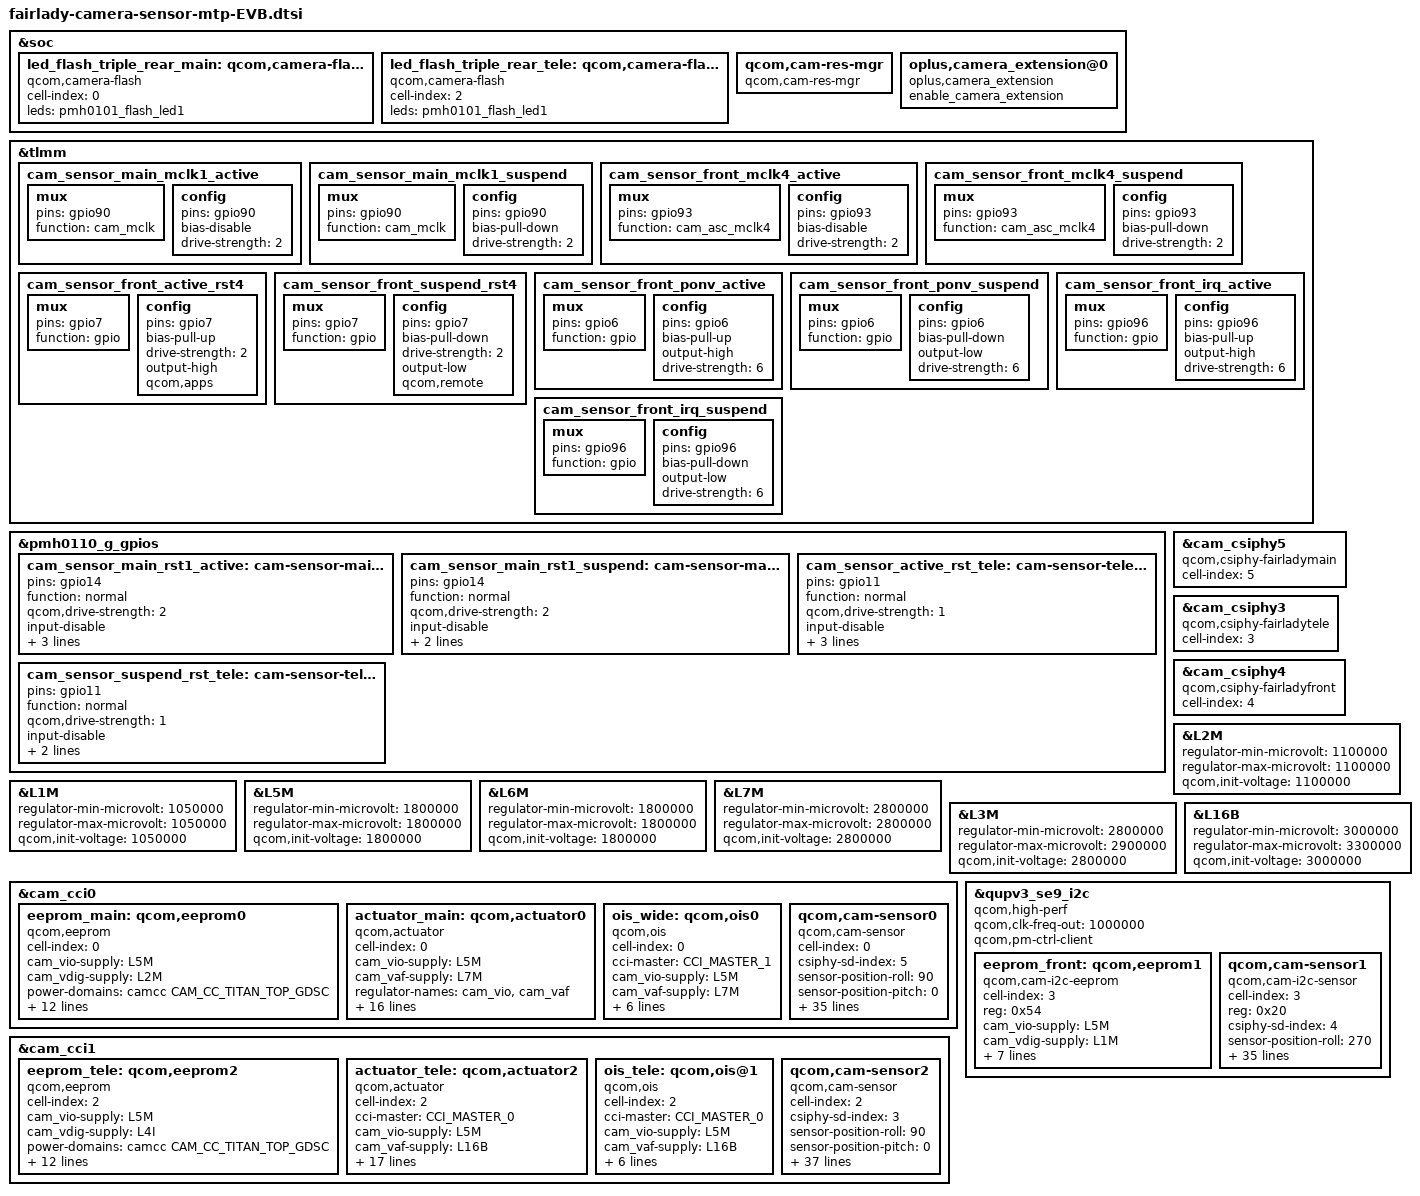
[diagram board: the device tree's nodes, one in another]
// SPDX-License-Identifier: BSD-3-Clause
/*
 * Copyright (c) 2024 Qualcomm Innovation Center, Inc. All rights reserved.
 */

#include <dt-bindings/msm-camera.h>
#include "ftm_camera_settings.dtsi"

&soc {

	led_flash_triple_rear_main: qcom,camera-flash0 {
		cell-index = <0>;
		compatible = "qcom,camera-flash";
		leds = <&pmh0101_flash_led1>;
		status = "ok";
	};

	led_flash_triple_rear_tele: qcom,camera-flash2 {
		cell-index = <2>;
		compatible = "qcom,camera-flash";
		leds = <&pmh0101_flash_led1>;
		status = "ok";
	};

	qcom,cam-res-mgr {
		compatible = "qcom,cam-res-mgr";
		status = "ok";
	};

	oplus,camera_extension@0 {
		compatible = "oplus,camera_extension";
		enable_camera_extension;
		status = "ok";
	};
};


&tlmm {
	cam_sensor_main_mclk1_active: cam_sensor_main_mclk1_active {
		/* MCLK1 */
		mux {
			pins = "gpio90";
			function = "cam_mclk";
		};

		config {
			pins = "gpio90";
			bias-disable; /* No PULL */
			drive-strength = <2>; /* 2 MA */
		};
	};

	cam_sensor_main_mclk1_suspend: cam_sensor_main_mclk1_suspend {
		/* MCLK1 */
		mux {
			pins = "gpio90";
			function = "cam_mclk";
		};

		config {
			pins = "gpio90";
			bias-pull-down; /* PULL DOWN */
			drive-strength = <2>; /* 2 MA */
		};
	};

	cam_sensor_front_mclk4_active: cam_sensor_front_mclk4_active {
		/* MCLK4 */
		mux {
			pins = "gpio93";
			function = "cam_asc_mclk4";
		};

		config {
			pins = "gpio93";
			bias-disable; /* No PULL */
			drive-strength = <2>; /* 2 MA */
		};
	};

	cam_sensor_front_mclk4_suspend: cam_sensor_front_mclk4_suspend {
		/* MCLK4 */
		mux {
			pins = "gpio93";
			function = "cam_asc_mclk4";
		};

		config {
			pins = "gpio93";
			bias-pull-down; /* PULL DOWN */
			drive-strength = <2>; /* 2 MA */
		};
	};

	cam_sensor_front_active_rst4: cam_sensor_front_active_rst4 {
		mux {
			pins = "gpio7";
			function = "gpio";
		};

		config {
			pins = "gpio7";
			bias-pull-up; /* PULL UP*/
			drive-strength = <2>; /* 2 MA */
			output-high;
			qcom,apps;
		};
	};

	cam_sensor_front_suspend_rst4: cam_sensor_front_suspend_rst4 {
		mux {
			pins = "gpio7";
			function = "gpio";
		};

		config {
			pins = "gpio7";
			bias-pull-down; /* PULL DOWN */
			drive-strength = <2>; /* 2 MA */
			output-low;
			qcom,remote;
		};
	};

	cam_sensor_front_ponv_active: cam_sensor_front_ponv_active {
		/* PONV */
		mux {
			pins = "gpio6";
			function = "gpio";
		};

		config {
			pins = "gpio6";
			bias-pull-up; /* PULL UP*/
			output-high;
			drive-strength = <6>; /* 2 MA */
		};
	};

	cam_sensor_front_ponv_suspend: cam_sensor_front_ponv_suspend {
		/* PONV */
		mux {
			pins = "gpio6";
			function = "gpio";
		};

		config {
			pins = "gpio6";


			bias-pull-down; /* PULL DOWN */
			output-low;
			drive-strength = <6>; /* 2 MA */
		};
	};

	cam_sensor_front_irq_active: cam_sensor_front_irq_active {
		/* TRQ */
		mux {
			pins = "gpio96";
			function = "gpio";
		};

		config {
			pins = "gpio96";
			bias-pull-up; /* PULL UP*/
			output-high;
			drive-strength = <6>; /* 2 MA */
		};
	};

	cam_sensor_front_irq_suspend: cam_sensor_front_irq_suspend {
		/* IRQ */
		mux {
			pins = "gpio96";
			function = "gpio";
		};

		config {
			pins = "gpio96";


			bias-pull-down; /* PULL DOWN */
			output-low;
			drive-strength = <6>; /* 2 MA */
		};
	};
};


&pmh0110_g_gpios {
    cam_sensor_main_rst1_active: cam-sensor-main-rst1-active-state {
		pins = "gpio14";
		function = "normal";
		qcom,drive-strength = <2>;
		input-disable;
		output-enable;
		output-high;
		power-source = <1>; /* 1.2 V */
	};

	cam_sensor_main_rst1_suspend: cam-sensor-main-rst1-suspend-state {
		pins = "gpio14";
		function = "normal";
		qcom,drive-strength = <2>;
		input-disable;
		output-enable;
		output-low;
	};

	cam_sensor_active_rst_tele: cam-sensor-tele-active-state {
		pins = "gpio11";
		function = "normal";
		qcom,drive-strength = <1>;
		input-disable;
		output-enable;
		output-high;
		power-source = <1>; /* 1.2 V */
	};
	
	cam_sensor_suspend_rst_tele: cam-sensor-tele-suspend-state {
		pins = "gpio11";
		function = "normal";
		qcom,drive-strength = <1>;
		input-disable;
		output-enable;
		output-low;
	};
};

&cam_csiphy5{
	cell-index = <5>;
	compatible = "qcom,csiphy-fairladymain", "qcom,csiphy";
};

&cam_csiphy3{
	cell-index = <3>;
	compatible = "qcom,csiphy-fairladytele", "qcom,csiphy";
};

&cam_csiphy4{
	cell-index = <4>;
	compatible = "qcom,csiphy-fairladyfront", "qcom,csiphy";
};

&L2M {
  regulator-min-microvolt = <1100000>;
  regulator-max-microvolt = <1100000>;
  qcom,init-voltage = <1100000>;
};

&L1M {
  regulator-min-microvolt = <1050000>;
  regulator-max-microvolt = <1050000>;
  qcom,init-voltage = <1050000>;
};

&L5M {
  regulator-min-microvolt = <1800000>;
  regulator-max-microvolt = <1800000>;
  qcom,init-voltage = <1800000>;
};

&L6M {
  regulator-min-microvolt = <1800000>;
  regulator-max-microvolt = <1800000>;
  qcom,init-voltage = <1800000>;
};

&L7M {
  regulator-min-microvolt = <2800000>;
  regulator-max-microvolt = <2800000>;
  qcom,init-voltage = <2800000>;
};

&L3M {
  regulator-min-microvolt = <2800000>;
  regulator-max-microvolt = <2900000>;
  qcom,init-voltage = <2800000>;
};

&L16B {
	regulator-min-microvolt = <3000000>;
	regulator-max-microvolt = <3300000>;
	qcom,init-voltage = <3000000>;
};

&cam_cci0 {
	eeprom_main: qcom,eeprom0 {
		cell-index = <0>;
		compatible = "qcom,eeprom";
		cam_vio-supply = <&L5M>;
		cam_vdig-supply = <&L2M>;
		power-domains = <&camcc CAM_CC_TITAN_TOP_GDSC>;
		cam_vana-supply = <&L3M>;
		cam_vaf-supply = <&L7M>;
		cam_v_custom1-supply = <&L6M>;
		regulator-names = "cam_vio", "cam_vdig", "cam_vana",
			"cam_vaf", "cam_v_custom1";
		rgltr-cntrl-support;
		rgltr-min-voltage = <1800000 1100000 2800000 2800000 1800000>;
		rgltr-max-voltage = <1800000 1100000 2800000 2800000 1800000>;
		rgltr-load-current = <3000 15000 3000 6000 3000>;
		cci-master = <CCI_MASTER_1>;
		status = "ok";
	};

	actuator_main: qcom,actuator0 {
		cell-index = <0>;
		compatible = "qcom,actuator";
		cam_vio-supply = <&L5M>;
		cam_vaf-supply = <&L7M>;
		regulator-names = "cam_vio", "cam_vaf";
		rgltr-cntrl-support;
		rgltr-min-voltage = <1800000 2800000>;
		rgltr-max-voltage = <1800000 2800000>;
		rgltr-load-current = <3000 6000>;
		cci-master = <CCI_MASTER_1>;
		actuator,name = "dw9827c_main";
		cci_client_sid = <0x18>;
		sds-lock-support;
		//                       reg_addr   addr_type   reg_data    data_type   delay       data_mask
		sds-lock-reg-setting = < 0x02           1         0x40        1          10            0x00 >,
		                       < 0x02           1         0x40        1          10            0x00 >,
		                       < 0x00           1         0x80        1          5             0x00 >,
		                       < 0x02           1         0x00        1          5             0x00 >;
		disable-auto-standby;
		//                                   reg_addr   addr_type   reg_data    data_type   delay       data_mask
		disable-auto-standby-reg-setting = < 0x02           1         0x40        1          5            0x00 >,
		                                   < 0x34           1         0x85        1          1            0x00 >,
		                                   < 0x7D           1         0x00        1          1            0x00 >,
		                                   < 0x03           1         0x01        1          10           0x00 >,
		                                   < 0x34           1         0x52        1          1            0x00 >,
		                                   < 0x04           1         0x01        1          20           0x00 >;
		status = "ok";
	};

	ois_wide: qcom,ois0 {
		cell-index = <0>;
		compatible = "qcom,ois";
		cci-master = <CCI_MASTER_1>;
		cam_vio-supply = <&L5M>;
		cam_vaf-supply = <&L7M>;
		power-domains = <&camcc CAM_CC_TITAN_TOP_GDSC>;
		regulator-names = "cam_vio","cam_vaf";
		rgltr-cntrl-support;
		rgltr-min-voltage = <1800000 2800000>;
		rgltr-max-voltage = <1800000 2800000>;
		rgltr-load-current = <3000 6000>;
		// ois_gyro,position=<3>;
		// ois_gyro,type=<3>;
		// ois,type=<0>;
		// //ois,name="bu63169";//??
		// ois_module,vendor=<1>;
		// ois_actuator,vednor=<2>;
		// ois,fw=<1>;
		status = "ok";
	};

	//main sensor
	qcom,cam-sensor0 {
		cell-index = <0>;
		compatible = "qcom,cam-sensor";
		csiphy-sd-index = <5>;
		sensor-position-roll = <90>;
		sensor-position-pitch = <0>;
		sensor-position-yaw = <180>;
		eeprom-src = <&eeprom_main>;
		actuator-src = <&actuator_main>;
		ois-src = <&ois_wide>;
		led-flash-src = <&led_flash_triple_rear_main>;
		cam_vio-supply = <&L5M>;
		cam_vdig-supply = <&L2M>;
		power-domains = <&camcc CAM_CC_TITAN_TOP_GDSC>;
		cam_vana-supply = <&L3M>;
		cam_vaf-supply = <&L7M>;
		cam_v_custom1-supply = <&L6M>;
		regulator-names = "cam_vio", "cam_vdig", "cam_vana",
			"cam_vaf", "cam_v_custom1";
		rgltr-cntrl-support;
		rgltr-min-voltage = <1800000 1100000 2800000 2800000 1800000>;
		rgltr-max-voltage = <1800000 1100000 2800000 2800000 1800000>;
		rgltr-load-current = <3000 15000 3000 6000 3000>;
		gpio-no-mux = <0>;
		pinctrl-names = "cam_default", "cam_suspend";
		pinctrl-0 = <&cam_sensor_main_mclk1_active
				 &cam_sensor_main_rst1_active>;
		pinctrl-1 = <&cam_sensor_main_mclk1_suspend
				 &cam_sensor_main_rst1_suspend>;
		gpios = <&tlmm 90 0>,
			<&pmh0110_g_gpios 14 0>;
		gpio-reset = <1>;
		gpio-req-tbl-num = <0 1>;
		gpio-req-tbl-flags = <1 0>;
		gpio-req-tbl-label = "CAMIF_MCLK1",
			"CAM_RESET1";
		cci-master = <CCI_MASTER_1>;
		clocks = <&cambistmclkcc CAM_BIST_MCLK_CC_MCLK1_CLK>;
		clock-names = "cam_clk";
		clock-cntl-level = "nominal";
		clock-rates = <19200000>;
		//enable_qsc_write_in_advance = <1>;
		//qsc_reg_addr = <0x2210>;
		//eeprom_slave_addr = <0xA0>;
		//qsc_data_size = <3072>;
		//write_qsc_addr = <0x1000>;
		ftm_setting_compatible = <'R' 0x0016 2 2 0x0906>;
		status = "ok";
	};
};

&cam_cci1 {

	eeprom_tele: qcom,eeprom2 {
		cell-index = <2>;
		compatible = "qcom,eeprom";
		cam_vio-supply = <&L5M>;
		cam_vdig-supply = <&L4I>;
		power-domains = <&camcc CAM_CC_TITAN_TOP_GDSC>;
		cam_vana-supply = <&L4M>;
		cam_vaf-supply = <&L16B>;
		regulator-names = "cam_vio", "cam_vdig", "cam_clk","cam_vana", "cam_vaf";
		rgltr-cntrl-support;
		rgltr-min-voltage = <1800000 1048000 0 2200000 3300000>;
		rgltr-max-voltage = <1800000 1048000 0 2200000 3300000>;
		rgltr-load-current = <300000 1200000 0 300000 600000>;
		cci-master = <CCI_MASTER_0>;
		status = "ok";
	};

	actuator_tele: qcom,actuator2 {
		cell-index = <2>;
		compatible = "qcom,actuator";
		cci-master = <CCI_MASTER_0>;
		cam_vio-supply = <&L5M>;
		cam_vaf-supply = <&L16B>;
		regulator-names = "cam_vio", "cam_vaf";
		rgltr-cntrl-support;
		rgltr-min-voltage = <1800000 3300000>;
		rgltr-max-voltage = <1800000 3300000>;
		rgltr-load-current = <3000 600000>;
		is_update_pid;
		actuator,name = "dw9827c";
		cci_client_sid = <0x1E>;
		sds-lock-support;
		//                       reg_addr   addr_type   reg_data    data_type   delay       data_mask
		sds-lock-reg-setting = < 0x02           1         0x40        1          10            0x00 >,
		                       < 0x02           1         0x40        1          10            0x00 >,
		                       < 0x00           1         0x80        1          5             0x00 >,
		                       < 0x02           1         0x00        1          5             0x00 >;
		disable-auto-standby;
		//                                   reg_addr   addr_type   reg_data    data_type   delay       data_mask
		disable-auto-standby-reg-setting = < 0x02           1         0x40        1          5            0x00 >,
		                                   < 0x34           1         0x85        1          1            0x00 >,
		                                   < 0x7D           1         0x01        1          1            0x00 >,
		                                   < 0x03           1         0x01        1          10           0x00 >,
		                                   < 0x34           1         0x52        1          1            0x00 >,
		                                   < 0x04           1         0x01        1          20           0x00 >;
		status = "ok";
	};

	ois_tele: qcom,ois@1 {
		cell-index = <2>;
		compatible = "qcom,ois";
		cci-master = <CCI_MASTER_0>;
		cam_vio-supply = <&L5M>;
		cam_vaf-supply = <&L16B>;
		power-domains = <&camcc CAM_CC_TITAN_TOP_GDSC>;
		regulator-names = "cam_vio","cam_vaf";
		rgltr-cntrl-support;
		rgltr-min-voltage = <1800000 3300000>;
		rgltr-max-voltage = <1800000 3300000>;
		rgltr-load-current = <3000 600000>;
		// ois_gyro,position=<3>;
		// ois_gyro,type=<0>;
		// ois,type=<1>;
		// ois,name="sem1217s";
		// ois_module,vendor=<0>;
		// ois_actuator,vednor=<7>;
		// ois,fw=<1>;
		// download,fw=<1>;
		// ois_eis_function = <6>;
		// actuator_ois_eeprom_merge = <1>;
		status = "ok";
	};

	//tele sensor
	qcom,cam-sensor2 {
		cell-index = <2>;
		compatible = "qcom,cam-sensor";
		csiphy-sd-index = <3>;
		sensor-position-roll = <90>;
		sensor-position-pitch = <0>;
		sensor-position-yaw = <180>;
		eeprom-src = <&eeprom_tele>;
		ois-src = <&ois_tele>;
		actuator-src = <&actuator_tele>;
		led-flash-src = <&led_flash_triple_rear_tele>;
		cam_vio-supply = <&L5M>;
		cam_vdig-supply = <&L4I>;
		power-domains = <&camcc CAM_CC_TITAN_TOP_GDSC>;
		cam_vana-supply = <&L4M>;
		cam_vaf-supply = <&L16B>;
		regulator-names = "cam_vio", "cam_vdig", "cam_clk","cam_vana", "cam_vaf";
		rgltr-cntrl-support;
		rgltr-min-voltage = <1800000 1048000 0 2200000 3300000>;
		rgltr-max-voltage = <1800000 1048000 0 2200000 3300000>;
		rgltr-load-current = <300000 1200000 0 300000 600000>;
		gpio-no-mux = <0>;
		pinctrl-names = "cam_default", "cam_suspend";
		pinctrl-0 = <&cam_sensor_mclk3_active
				 &cam_sensor_active_rst_tele>;
		pinctrl-1 = <&cam_sensor_mclk3_suspend
				 &cam_sensor_suspend_rst_tele>;
		gpios = <&tlmm 92 0>,
			<&pmh0110_i_gpios 11 0>;
		gpio-reset = <1>;
		gpio-req-tbl-num = <0 1>;
		gpio-req-tbl-flags = <1 0>;
		gpio-req-tbl-label = "CAMIF_MCLK3",
					"CAM_RESET3";
		cci-master = <CCI_MASTER_0>;
		clocks = <&cambistmclkcc CAM_BIST_MCLK_CC_MCLK3_CLK>;
		clock-names = "cam_clk";
		clock-cntl-level = "nominal";
		clock-rates = <19200000>;
		ftm_setting_compatible = <'W' 0xFCFC 2 2 0x4000  'R' 0x0000 2 2 0x38E5>;
		status = "ok";
		is_need_clk_stretch = <1>;
	};
};

&qupv3_se9_i2c {
	status = "ok";
	qcom,high-perf;
	qcom,clk-freq-out = <1000000>;
	qcom,pm-ctrl-client;
	
	eeprom_front: qcom,eeprom1 {
		cell-index = <3>;
		reg = <0x54>;
		compatible = "qcom,cam-i2c-eeprom";
		cam_vio-supply = <&L5M>;
		cam_vdig-supply = <&L1M>;
		cam_vana-supply = <&L3M>;
		power-domains = <&camcc CAM_CC_TITAN_TOP_GDSC>;
		regulator-names = "cam_vio", "cam_vdig", "cam_vana";
		rgltr-cntrl-support;
		rgltr-min-voltage = <1800000 1050000 2800000>;
		rgltr-max-voltage = <1800000 1050000 2800000>;
		rgltr-load-current = <300000 1500000 300000>;
		status = "ok";
	};

	// front camera
	qcom,cam-sensor1 {
		cell-index = <3>;
		reg = <0x20>;
		compatible = "qcom,cam-i2c-sensor";
		csiphy-sd-index = <4>;
		sensor-position-roll = <270>;
		sensor-position-pitch = <0>;
		sensor-position-yaw = <180>;
		eeprom-src = <&eeprom_front>;
		cam_vio-supply = <&L5M>;
		cam_vdig-supply = <&L1M>;
		cam_vana-supply = <&L3M>;
		power-domains = <&camcc CAM_CC_TITAN_TOP_GDSC>;
		regulator-names = "cam_vio", "cam_vdig", "cam_vana";
		rgltr-cntrl-support;
		aon-camera-id = <AON_CAM1>;
		rgltr-min-voltage = <1800000 1050000 2800000>;
		rgltr-max-voltage = <1800000 1050000 2800000>;
		rgltr-load-current = <300000 1500000 300000>;
		gpio-no-mux = <0>;
		pinctrl-names = "cam_default", "cam_suspend";
		pinctrl-0 = <&cam_sensor_front_mclk4_active
				 &cam_sensor_front_active_rst4
                 &cam_sensor_front_ponv_active
                 &cam_sensor_front_irq_active>;
		pinctrl-1 = <&cam_sensor_front_mclk4_suspend
				 &cam_sensor_front_suspend_rst4
                 &cam_sensor_front_ponv_suspend
                 &cam_sensor_front_irq_suspend>;
		gpios = <&tlmm 93 0>,
			<&tlmm 7 0>,
            <&tlmm 6 0>,
            <&tlmm 96 0>;
		gpio-reset = <1>;
		gpio-req-tbl-num = <0 1 2 3>;
		gpio-req-tbl-flags = <1 0 0 0>;
		gpio-req-tbl-label = "CAMIF_MCLK4",
					"CAM_RESET4",
					"CAM_PONV_FRONT",
                    "CAM_IRQ_FRONT";
		clocks = <&cambistmclkcc CAM_BIST_MCLK_CC_MCLK4_CLK>;
		clock-names = "cam_clk";
		clock-cntl-level = "nominal";
		clock-rates = <19200000>;
		swremosaic_sensor_id = <0x0471>;
		ftm_setting_compatible = <'R' 0x0016 2 2 0x0615
					  'R' 0x0016 2 2 0x0471
					  'W' 0x0A02 2 1 0x7F
					  'W' 0x0A00 2 1 0x01
					  'R' 0x0A1F 2 1 0x00B4>; // expect camera_0016_0615_0A1F_0034 camera_0016_0615_0A1F_0038 or camera_0016_0615_0A1F_00B4 camera_0016_0471_0A1F_0000
		status = "ok";
	};

};

